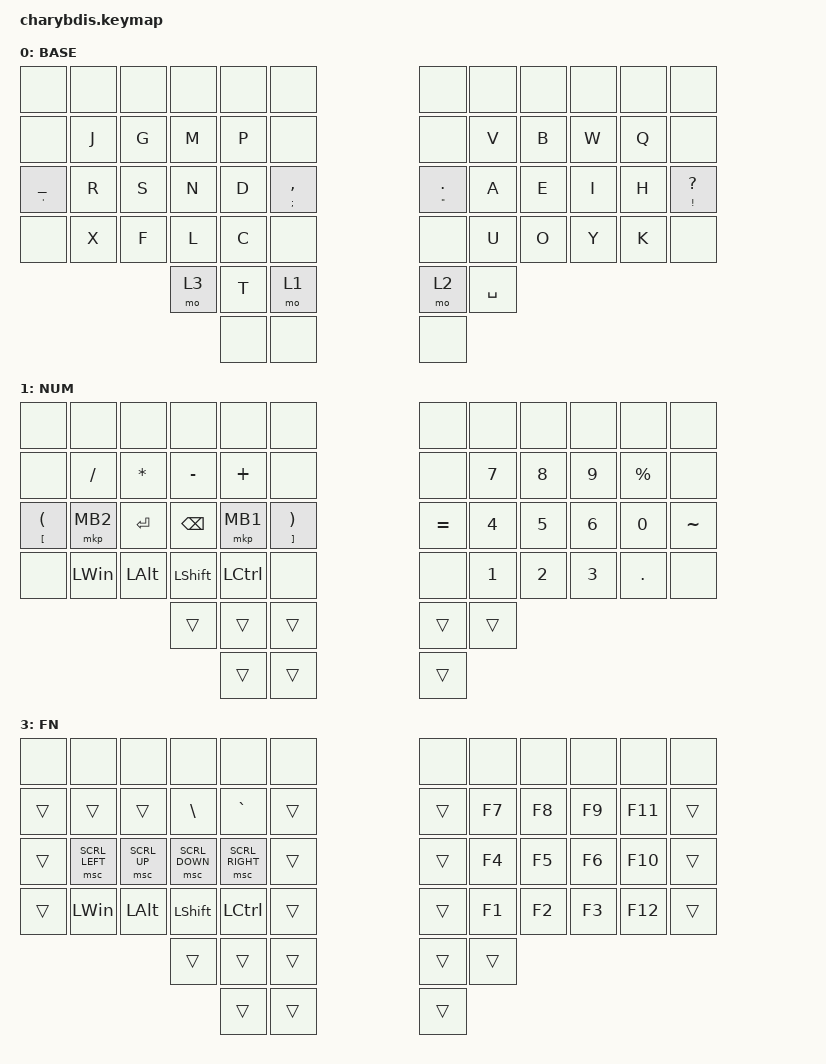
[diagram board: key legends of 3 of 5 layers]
#include <dt-bindings/zmk/mouse.h>
#include <input/processors.dtsi>
#include <zephyr/dt-bindings/input/input-event-codes.h>
#include <behaviors.dtsi>
#include <dt-bindings/zmk/bt.h>
#include <dt-bindings/zmk/keys.h>
#include <dt-bindings/zmk/pointing.h>

#define ZMK_POINTING_DEFAULT_MOVE_VAL 1000 // 600
#define ZMK_POINTING_DEFAULT_SCRL_VAL 12   // 10

&lt {
    tapping-term-ms = <200>;
    flavor = "balanced";
    quick-tap-ms = <150>;
};

&mmv_input_listener { input-processors = <&zip_xy_scaler 2 1>; };

&msc_input_listener { input-processors = <&zip_scroll_scaler 2 1>; };

&msc {
    acceleration-exponent = <0>;      // 0
    time-to-max-speed-ms = <100>;       // 300
    delay-ms = <0>;                   // 0
};

&mmv {
    time-to-max-speed-ms = <300>;
    acceleration-exponent = <1>;
    trigger-period-ms = <16>;
};

/ {
    // 上下滚动编码器行为

    scroll_vertical_encoder: scroll_vertical_encoder {
        compatible = "zmk,behavior-sensor-rotate";
        #sensor-binding-cells = <0>;
        bindings = <&msc SCRL_DOWN>, <&msc SCRL_UP>;

        tap-ms = <100>;
    };

    // 左右滚动编码器行为

    scroll_horizontal_encoder: scroll_horizontal_encoder {
        compatible = "zmk,behavior-sensor-rotate";
        #sensor-binding-cells = <0>;
        bindings = <&msc SCRL_LEFT>, <&msc SCRL_RIGHT>;

        tap-ms = <100>;
    };

    behaviors {
    };

    combos {
        compatible = "zmk,combos";

        btLoader {
            bindings = <&bootloader>;
            key-positions = <13 22>;
            timeout-ms = <30>;
            layers = <2>;
        };

        z {
            bindings = <&kp Z>;
            key-positions = <21 22>;
            layers = <0>;
        };

        alt-tab {
            bindings = <&kp LC(LA(TAB))>;
            key-positions = <26 27 28>;
        };

        esc {
            bindings = <&kp ESCAPE>;
            key-positions = <31 32 33>;
        };

        uTools {
            bindings = <&kp LS(LA(LC(E)))>;
            key-positions = <28 31 32>;
        };

        Mouseless {
            bindings = <&kp LA(LS(LC(A)))>;
            key-positions = <27 28 31>;
        };

        Fn_to_Bluetooth {
            bindings = <&mo 4>;
            key-positions = <14 15>;
            layers = <3>;
        };

        Lower_right {
            bindings = <&kp RA(RC(F4))>;
            key-positions = <43 44 45>;
        };

        Lower_left {
            bindings = <&kp LC(LA(F6))>;
            key-positions = <40 39 38>;
        };
    };

    keymap {
        compatible = "zmk,keymap";

        BASE {
            bindings = <
&none               &none  &none  &none  &none  &none                  &none                     &none      &none  &none  &none  &none
&none               &kp J  &kp G  &kp M  &kp P  &none                  &none                     &kp V      &kp B  &kp W  &kp Q  &none
&mt SQT UNDERSCORE  &kp R  &kp S  &kp N  &kp D  &mt SEMICOLON COMMA    &mt DOUBLE_QUOTES PERIOD  &kp A      &kp E  &kp I  &kp H  &mt EXCLAMATION QUESTION
&none               &kp X  &kp F  &kp L  &kp C  &none                  &none                     &kp U      &kp O  &kp Y  &kp K  &none
                                  &mo 3  &kp T  &mo 1                  &mo 2                     &kp SPACE
                                         &none  &none                  &none
            >;

            sensor-bindings =
                <&scroll_vertical_encoder>,
                // 编码器1：上下滚动,,,,,
                <&scroll_horizontal_encoder>;

            // 编码器2：左右滚动
        };

        NUM {
            bindings = <
&none                              &none      &none         &none          &none      &none                                  &none      &none   &none   &none   &none        &none
&none                              &kp SLASH  &kp ASTERISK  &kp MINUS      &kp PLUS   &none                                  &none      &kp N7  &kp N8  &kp N9  &kp PERCENT  &none
&mt LEFT_BRACKET LEFT_PARENTHESIS  &mkp MB2   &kp ENTER     &kp BACKSPACE  &mkp MB1   &mt RIGHT_BRACKET RIGHT_PARENTHESIS    &kp EQUAL  &kp N4  &kp N5  &kp N6  &kp N0       &kp TILDE
&none                              &kp LWIN   &kp LEFT_ALT  &kp LSHIFT     &kp LCTRL  &none                                  &none      &kp N1  &kp N2  &kp N3  &kp PERIOD   &none
                                                            &trans         &trans     &trans                                 &trans     &trans
                                                                           &trans     &trans                                 &trans
            >;
        };

        NAV {
            bindings = <
&none   &none           &none          &none              &none            &none           &none            &none              &none                                       &none          &none          &none
&trans  &kp LC(MINUS)   &kp LC(PG_UP)  &kp LC(PAGE_DOWN)  &kp LC(EQUAL)    &trans          &trans           &kp C_PP           &mt LC(LA(LEFT_ARROW)) LA(LC(RIGHT_ARROW))  &kp LC(LA(G))  &kp LA(LS(D))  &trans
&trans  &kp LEFT_ARROW  &kp UP_ARROW   &kp DOWN_ARROW     &kp RIGHT_ARROW  &kp C_VOL_DN    &kp C_VOLUME_UP  &kp LS(LA(LC(H)))  &kp BACKSPACE                               &kp ENTER      &kp DELETE     &trans
&trans  &kp HOME        &kp PG_UP      &kp PG_DN          &kp END          &trans          &trans           &kp RCTRL          &kp RIGHT_SHIFT                             &kp RALT       &kp RGUI       &trans
                                       &trans             &kp TAB          &trans          &trans           &trans
                                                          &trans           &trans          &trans
            >;
        };

        FN {
            bindings = <
&none   &none           &none         &none           &none            &none     &none   &none   &none   &none   &none    &none
&trans  &trans          &trans        &kp BACKSLASH   &kp GRAVE        &trans    &trans  &kp F7  &kp F8  &kp F9  &kp F11  &trans
&trans  &msc SCRL_LEFT  &msc SCRL_UP  &msc SCRL_DOWN  &msc SCRL_RIGHT  &trans    &trans  &kp F4  &kp F5  &kp F6  &kp F10  &trans
&trans  &kp LEFT_WIN    &kp LEFT_ALT  &kp LSHIFT      &kp LCTRL        &trans    &trans  &kp F1  &kp F2  &kp F3  &kp F12  &trans
                                      &trans          &trans           &trans    &trans  &trans
                                                      &trans           &trans    &trans
            >;
        };

        Bluetooth {
            bindings = <
&none  &none  &none  &none  &none  &none    &none  &none         &none         &none         &none           &none
&none  &none  &none  &none  &none  &none    &none  &none         &none         &none         &none           &none
&none  &none  &none  &none  &none  &none    &none  &bt BT_SEL 0  &bt BT_SEL 1  &bt BT_SEL 2  &none           &none
&none  &none  &none  &none  &none  &none    &none  &bt BT_CLR    &none         &none         &bt BT_CLR_ALL  &none
                     &none  &none  &none    &none  &none
            >;
        };
    };
};
